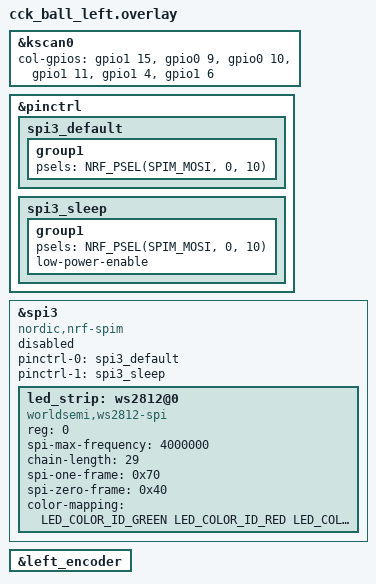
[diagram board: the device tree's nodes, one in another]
/*
 * Copyright (c) 2020 ZMK Contributors
 * SPDX-License-Identifier: MIT
 */

#include "cck_ball.dtsi"

&kscan0 {
    col-gpios
        = <&gpio1 15 GPIO_ACTIVE_HIGH>
        , <&gpio0 9 GPIO_ACTIVE_HIGH>
        , <&gpio0 10 GPIO_ACTIVE_HIGH>
        , <&gpio1 11 GPIO_ACTIVE_HIGH>
        , <&gpio1 4 GPIO_ACTIVE_HIGH>
        , <&gpio1 6 GPIO_ACTIVE_HIGH>
        ;
};

// RGB bus retained from CCK-BALL.
&pinctrl {
    spi3_default: spi3_default {
        group1 {
            psels = <NRF_PSEL(SPIM_MOSI, 0, 10)>;
        };
    };
    spi3_sleep: spi3_sleep {
        group1 {
            psels = <NRF_PSEL(SPIM_MOSI, 0, 10)>;
            low-power-enable;
        };
    };
};

&spi3 {
    compatible = "nordic,nrf-spim";
    status = "okay";

    pinctrl-0 = <&spi3_default>;
    pinctrl-1 = <&spi3_sleep>;
    pinctrl-names = "default", "sleep";

    led_strip: ws2812@0 {
        compatible = "worldsemi,ws2812-spi";
        reg = <0>;
        spi-max-frequency = <4000000>;
        chain-length = <29>;
        spi-one-frame = <0x70>;
        spi-zero-frame = <0x40>;
        color-mapping = <LED_COLOR_ID_GREEN
                         LED_COLOR_ID_RED
                         LED_COLOR_ID_BLUE>;
    };
};

&left_encoder {
    status = "okay";
};

/* Legacy unused RGB SPI3 shared P0.10 with a matrix column.
 * Keep the LED description for provenance but do not claim that pin at boot.
 * No RGB feature is enabled in this STENO build. */
&spi3 { status = "disabled"; };
